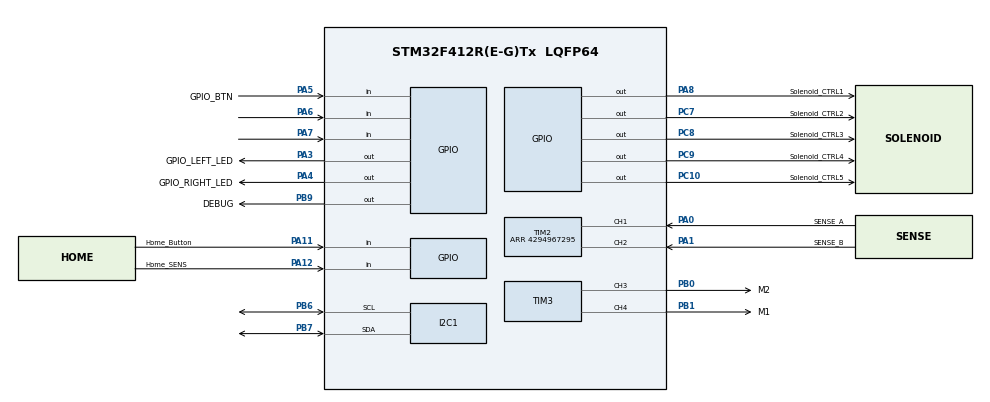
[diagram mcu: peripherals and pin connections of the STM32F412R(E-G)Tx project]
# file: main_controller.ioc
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Mcu.Family=STM32F4
Mcu.Name=STM32F412R(E-G)Tx
Mcu.Package=LQFP64
Mcu.UserConstants=TIM3autoreload,TIMxfrequency/((TIM3prescaler+1)*TIM3frequency);TIM3frequency,1000;TIM3prescaler,0;TIMxfrequency,16000000;TIM6prescaler,0;TIM6frequency,1000;TIM6autoreload,TIMxfrequency/((Tim6prescaler+1)*Tim6frequency)
NVIC.FPU_IRQn=true\:0\:0\:false\:false\:true\:true\:false\:true
NVIC.PriorityGroup=NVIC_PRIORITYGROUP_4
NVIC.TIM2_IRQn=true\:0\:0\:false\:false\:true\:true\:true\:true
NVIC.TIM3_IRQn=true\:0\:0\:false\:false\:true\:true\:true\:true
NVIC.TIM6_IRQn=true\:0\:0\:false\:false\:true\:true\:true\:true
NVIC.TIM8_UP_TIM13_IRQn=true\:15\:0\:false\:false\:true\:false\:true\:true
NVIC.TimeBase=TIM8_UP_TIM13_IRQn
NVIC.TimeBaseIP=TIM8
PA0.GPIO_Label=SENSE_A
PA0.Signal=S_TIM2_CH1_ETR
PA1.GPIO_Label=SENSE_B
PA1.Signal=S_TIM2_CH2
PA11.GPIO_Label=Home_Button
PA11.GPIO_PuPd=GPIO_NOPULL
PA11.Signal=GPIO_Input
PA12.GPIO_Label=Home_SENS
PA12.GPIO_PuPd=GPIO_PULLUP
PA12.Signal=GPIO_Input
PA13.GPIO_Label=M_SWDIO
PA13.Mode=Trace_Asynchronous_SW
PA13.Signal=SYS_JTMS-SWDIO
PA14.GPIO_Label=M_SWCLK
PA14.Mode=Trace_Asynchronous_SW
PA14.Signal=SYS_JTCK-SWCLK
PA3.GPIO_Label=GPIO_LEFT_LED
PA3.Signal=GPIO_Output
PA4.GPIO_Label=GPIO_RIGHT_LED
PA4.Signal=GPIO_Output
PA5.GPIO_Label=GPIO_BTN
PA5.GPIO_PuPd=GPIO_PULLUP
PA5.Signal=GPIO_Input
PA6.GPIO_PuPd=GPIO_PULLUP
PA6.Signal=GPIO_Input
PA7.GPIO_PuPd=GPIO_PULLUP
PA7.Signal=GPIO_Input
PA8.GPIO_Label=Solenoid_CTRL1
PA8.Signal=GPIO_Output
PB0.GPIO_Label=M2
PB0.GPIO_PuPd=GPIO_NOPULL
PB0.Signal=S_TIM3_CH3
PB1.GPIO_Label=M1
PB1.Signal=S_TIM3_CH4
PB3.GPIO_Label=M_SWO
PB3.Mode=Trace_Asynchronous_SW
PB3.Signal=SYS_JTDO-SWO
PB6.Mode=I2C
PB6.Signal=I2C1_SCL
PB7.Mode=I2C
PB7.Signal=I2C1_SDA
PB9.GPIO_Label=DEBUG
PB9.Signal=GPIO_Output
PC10.GPIO_Label=Solenoid_CTRL5
PC10.Signal=GPIO_Output
PC7.GPIO_Label=Solenoid_CTRL2
PC7.Signal=GPIO_Output
PC8.GPIO_Label=Solenoid_CTRL3
PC8.Signal=GPIO_Output
PC9.GPIO_Label=Solenoid_CTRL4
PC9.Signal=GPIO_Output
PH0\ -\ OSC_IN.Mode=HSE-External-Oscillator
PH0\ -\ OSC_IN.Signal=RCC_OSC_IN
PH1\ -\ OSC_OUT.Mode=HSE-External-Oscillator
PH1\ -\ OSC_OUT.Signal=RCC_OSC_OUT
ProjectManager.HeapSize=0x200
ProjectManager.StackSize=0x400
ProjectManager.TargetToolchain=CMake
RCC.CortexFreq_Value=16000000
RCC.HSE_VALUE=8000000
RCC.PLLSourceVirtual=RCC_PLLSOURCE_HSE
RCC.USBFreq_Value=48000000
RCC.VCOOutputFreq_Value=96000000
SH.S_TIM2_CH1_ETR.0=TIM2_CH1,Encoder_Interface
SH.S_TIM2_CH2.0=TIM2_CH2,Encoder_Interface
SH.S_TIM3_CH3.0=TIM3_CH3,PWM Generation3 CH3
SH.S_TIM3_CH4.0=TIM3_CH4,PWM Generation4 CH4
TIM2.AutoReloadPreload=TIM_AUTORELOAD_PRELOAD_DISABLE
TIM2.EncoderMode=TIM_ENCODERMODE_TI12
TIM2.IC1Filter=5
TIM2.IC2Filter=0
TIM2.Period=4294967295
TIM3.AutoReloadPreload=TIM_AUTORELOAD_PRELOAD_ENABLE
TIM3.Channel-PWM\ Generation3\ CH3=TIM_CHANNEL_3
TIM3.Channel-PWM\ Generation4\ CH4=TIM_CHANNEL_4
TIM3.Period=TIM3autoreload
TIM3.Prescaler=TIM3prescaler
TIM6.AutoReloadPreload=TIM_AUTORELOAD_PRELOAD_ENABLE
TIM6.Period=16000
TIM6.Prescaler=0
TIM6.TIM_MasterOutputTrigger=TIM_TRGO_UPDATE
VP_SYS_VS_tim8.Mode=TIM8
VP_TIM6_VS_ClockSourceINT.Mode=Enable_Timer
board=custom

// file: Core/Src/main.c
/* USER CODE BEGIN Header */
/**
  ******************************************************************************
  * @file           : main.c
  * @brief          : Main program body
  ******************************************************************************
  * @attention
  *
  * Copyright (c) 2026 STMicroelectronics.
  * All rights reserved.
  *
  * This software is licensed under terms that can be found in the LICENSE file
  * in the root directory of this software component.
  * If no LICENSE file comes with this software, it is provided AS-IS.
  *
  ******************************************************************************
  */
/* USER CODE END Header */
#include "main.h"

/* USER CODE BEGIN Includes */
#include "stm32f412rx.h"
#include "stm32f4xx_hal.h"

#include "app_main.h"

#include "SEGGER_RTT.h"
#include "SEGGER_RTT_Conf.h"
#include "stm32f4xx_hal.h"
#include "stm32f4xx_hal_tim.h"
#include <stdint.h>

/* USER CODE END Includes */

I2C_HandleTypeDef hi2c1;

TIM_HandleTypeDef htim2;
TIM_HandleTypeDef htim3;
TIM_HandleTypeDef htim6;

void SystemClock_Config(void);
static void MX_GPIO_Init(void);
static void MX_I2C1_Init(void);
static void MX_TIM3_Init(void);
static void MX_TIM2_Init(void);
static void MX_TIM6_Init(void);

int main(void)
{

  /* MCU Configuration--------------------------------------------------------*/

  /* Reset of all peripherals, Initializes the Flash interface and the Systick. */
  HAL_Init();

  /* Configure the system clock */
  SystemClock_Config();

  /* Initialize all configured peripherals */
  MX_GPIO_Init();
  MX_I2C1_Init();
  MX_TIM3_Init();
  MX_TIM2_Init();
  MX_TIM6_Init();
  /* USER CODE BEGIN 2 */
  HAL_TIM_Base_Start_IT(&htim6);

  App_Init();

  /* USER CODE END 2 */

  /* Infinite loop */
  while (1)
  {

    /* USER CODE BEGIN 3 */
    App_Tick();

  }
  /* USER CODE END 3 */
}

void SystemClock_Config(void)
{
  RCC_OscInitTypeDef RCC_OscInitStruct = {0};
  RCC_ClkInitTypeDef RCC_ClkInitStruct = {0};

  /** Configure the main internal regulator output voltage
  */
  __HAL_RCC_PWR_CLK_ENABLE();
  __HAL_PWR_VOLTAGESCALING_CONFIG(PWR_REGULATOR_VOLTAGE_SCALE1);

  /** Initializes the RCC Oscillators according to the specified parameters
  * in the RCC_OscInitTypeDef structure.
  */
  RCC_OscInitStruct.OscillatorType = RCC_OSCILLATORTYPE_HSI;
  RCC_OscInitStruct.HSIState = RCC_HSI_ON;
  RCC_OscInitStruct.HSICalibrationValue = RCC_HSICALIBRATION_DEFAULT;
  RCC_OscInitStruct.PLL.PLLState = RCC_PLL_NONE;
  if (HAL_RCC_OscConfig(&RCC_OscInitStruct) != HAL_OK)
  {
    Error_Handler();
  }

  /** Initializes the CPU, AHB and APB buses clocks
  */
  RCC_ClkInitStruct.ClockType = RCC_CLOCKTYPE_HCLK|RCC_CLOCKTYPE_SYSCLK
                              |RCC_CLOCKTYPE_PCLK1|RCC_CLOCKTYPE_PCLK2;
  RCC_ClkInitStruct.SYSCLKSource = RCC_SYSCLKSOURCE_HSI;
  RCC_ClkInitStruct.AHBCLKDivider = RCC_SYSCLK_DIV1;
  RCC_ClkInitStruct.APB1CLKDivider = RCC_HCLK_DIV1;
  RCC_ClkInitStruct.APB2CLKDivider = RCC_HCLK_DIV1;

  if (HAL_RCC_ClockConfig(&RCC_ClkInitStruct, FLASH_LATENCY_0) != HAL_OK)
  {
    Error_Handler();
  }
}

static void MX_I2C1_Init(void)
{

  hi2c1.Instance = I2C1;
  hi2c1.Init.ClockSpeed = 100000;
  hi2c1.Init.DutyCycle = I2C_DUTYCYCLE_2;
  hi2c1.Init.OwnAddress1 = 0;
  hi2c1.Init.AddressingMode = I2C_ADDRESSINGMODE_7BIT;
  hi2c1.Init.DualAddressMode = I2C_DUALADDRESS_DISABLE;
  hi2c1.Init.OwnAddress2 = 0;
  hi2c1.Init.GeneralCallMode = I2C_GENERALCALL_DISABLE;
  hi2c1.Init.NoStretchMode = I2C_NOSTRETCH_DISABLE;
  if (HAL_I2C_Init(&hi2c1) != HAL_OK)
  {
    Error_Handler();
  }

}

static void MX_TIM2_Init(void)
{

  TIM_Encoder_InitTypeDef sConfig = {0};
  TIM_MasterConfigTypeDef sMasterConfig = {0};

  htim2.Instance = TIM2;
  htim2.Init.Prescaler = 0;
  htim2.Init.CounterMode = TIM_COUNTERMODE_UP;
  htim2.Init.Period = 4294967295;
  htim2.Init.ClockDivision = TIM_CLOCKDIVISION_DIV1;
  htim2.Init.AutoReloadPreload = TIM_AUTORELOAD_PRELOAD_DISABLE;
  sConfig.EncoderMode = TIM_ENCODERMODE_TI12;
  sConfig.IC1Polarity = TIM_ICPOLARITY_RISING;
  sConfig.IC1Selection = TIM_ICSELECTION_DIRECTTI;
  sConfig.IC1Prescaler = TIM_ICPSC_DIV1;
  sConfig.IC1Filter = 5;
  sConfig.IC2Polarity = TIM_ICPOLARITY_RISING;
  sConfig.IC2Selection = TIM_ICSELECTION_DIRECTTI;
  sConfig.IC2Prescaler = TIM_ICPSC_DIV1;
  sConfig.IC2Filter = 0;
  if (HAL_TIM_Encoder_Init(&htim2, &sConfig) != HAL_OK)
  {
    Error_Handler();
  }
  sMasterConfig.MasterOutputTrigger = TIM_TRGO_RESET;
  sMasterConfig.MasterSlaveMode = TIM_MASTERSLAVEMODE_DISABLE;
  if (HAL_TIMEx_MasterConfigSynchronization(&htim2, &sMasterConfig) != HAL_OK)
  {
    Error_Handler();
  }

}

static void MX_TIM3_Init(void)
{

  TIM_MasterConfigTypeDef sMasterConfig = {0};
  TIM_OC_InitTypeDef sConfigOC = {0};

  htim3.Instance = TIM3;
  htim3.Init.Prescaler = TIM3prescaler;
  htim3.Init.CounterMode = TIM_COUNTERMODE_UP;
  htim3.Init.Period = TIM3autoreload;
  htim3.Init.ClockDivision = TIM_CLOCKDIVISION_DIV1;
  htim3.Init.AutoReloadPreload = TIM_AUTORELOAD_PRELOAD_ENABLE;
  if (HAL_TIM_PWM_Init(&htim3) != HAL_OK)
  {
    Error_Handler();
  }
  sMasterConfig.MasterOutputTrigger = TIM_TRGO_RESET;
  sMasterConfig.MasterSlaveMode = TIM_MASTERSLAVEMODE_DISABLE;
  if (HAL_TIMEx_MasterConfigSynchronization(&htim3, &sMasterConfig) != HAL_OK)
  {
    Error_Handler();
  }
  sConfigOC.OCMode = TIM_OCMODE_PWM1;
  sConfigOC.Pulse = 0;
  sConfigOC.OCPolarity = TIM_OCPOLARITY_HIGH;
  sConfigOC.OCFastMode = TIM_OCFAST_DISABLE;
  if (HAL_TIM_PWM_ConfigChannel(&htim3, &sConfigOC, TIM_CHANNEL_3) != HAL_OK)
  {
    Error_Handler();
  }
  if (HAL_TIM_PWM_ConfigChannel(&htim3, &sConfigOC, TIM_CHANNEL_4) != HAL_OK)
  {
    Error_Handler();
  }
  HAL_TIM_MspPostInit(&htim3);

}

static void MX_TIM6_Init(void)
{

  TIM_MasterConfigTypeDef sMasterConfig = {0};

  htim6.Instance = TIM6;
  htim6.Init.Prescaler = 0;
  htim6.Init.CounterMode = TIM_COUNTERMODE_UP;
  htim6.Init.Period = 16000;
  htim6.Init.AutoReloadPreload = TIM_AUTORELOAD_PRELOAD_ENABLE;
  if (HAL_TIM_Base_Init(&htim6) != HAL_OK)
  {
    Error_Handler();
  }
  sMasterConfig.MasterOutputTrigger = TIM_TRGO_UPDATE;
  sMasterConfig.MasterSlaveMode = TIM_MASTERSLAVEMODE_DISABLE;
  if (HAL_TIMEx_MasterConfigSynchronization(&htim6, &sMasterConfig) != HAL_OK)
  {
    Error_Handler();
  }

}

static void MX_GPIO_Init(void)
{
  GPIO_InitTypeDef GPIO_InitStruct = {0};

  /* GPIO Ports Clock Enable */
  __HAL_RCC_GPIOH_CLK_ENABLE();
  __HAL_RCC_GPIOA_CLK_ENABLE();
  __HAL_RCC_GPIOB_CLK_ENABLE();
  __HAL_RCC_GPIOC_CLK_ENABLE();

  /*Configure GPIO pin Output Level */
  HAL_GPIO_WritePin(GPIOA, GPIO_LEFT_LED_Pin|GPIO_RIGHT_LED_Pin|Solenoid_CTRL1_Pin, GPIO_PIN_RESET);

  /*Configure GPIO pin Output Level */
  HAL_GPIO_WritePin(GPIOC, Solenoid_CTRL2_Pin|Solenoid_CTRL3_Pin|Solenoid_CTRL4_Pin|Solenoid_CTRL5_Pin, GPIO_PIN_RESET);

  /*Configure GPIO pin Output Level */
  HAL_GPIO_WritePin(DEBUG_GPIO_Port, DEBUG_Pin, GPIO_PIN_RESET);

  /*Configure GPIO pins : GPIO_LEFT_LED_Pin GPIO_RIGHT_LED_Pin Solenoid_CTRL1_Pin */
  GPIO_InitStruct.Pin = GPIO_LEFT_LED_Pin|GPIO_RIGHT_LED_Pin|Solenoid_CTRL1_Pin;
  GPIO_InitStruct.Mode = GPIO_MODE_OUTPUT_PP;
  GPIO_InitStruct.Pull = GPIO_NOPULL;
  GPIO_InitStruct.Speed = GPIO_SPEED_FREQ_LOW;
  HAL_GPIO_Init(GPIOA, &GPIO_InitStruct);

  /*Configure GPIO pins : GPIO_BTN_Pin PA6 PA7 Home_SENS_Pin */
  GPIO_InitStruct.Pin = GPIO_BTN_Pin|GPIO_PIN_6|GPIO_PIN_7|Home_SENS_Pin;
  GPIO_InitStruct.Mode = GPIO_MODE_INPUT;
  GPIO_InitStruct.Pull = GPIO_PULLUP;
  HAL_GPIO_Init(GPIOA, &GPIO_InitStruct);

  /*Configure GPIO pins : Solenoid_CTRL2_Pin Solenoid_CTRL3_Pin Solenoid_CTRL4_Pin Solenoid_CTRL5_Pin */
  GPIO_InitStruct.Pin = Solenoid_CTRL2_Pin|Solenoid_CTRL3_Pin|Solenoid_CTRL4_Pin|Solenoid_CTRL5_Pin;
  GPIO_InitStruct.Mode = GPIO_MODE_OUTPUT_PP;
  GPIO_InitStruct.Pull = GPIO_NOPULL;
  GPIO_InitStruct.Speed = GPIO_SPEED_FREQ_LOW;
  HAL_GPIO_Init(GPIOC, &GPIO_InitStruct);

  /*Configure GPIO pin : Home_Button_Pin */
  GPIO_InitStruct.Pin = Home_Button_Pin;
  GPIO_InitStruct.Mode = GPIO_MODE_INPUT;
  GPIO_InitStruct.Pull = GPIO_NOPULL;
  HAL_GPIO_Init(Home_Button_GPIO_Port, &GPIO_InitStruct);

  /*Configure GPIO pin : DEBUG_Pin */
  GPIO_InitStruct.Pin = DEBUG_Pin;
  GPIO_InitStruct.Mode = GPIO_MODE_OUTPUT_PP;
  GPIO_InitStruct.Pull = GPIO_NOPULL;
  GPIO_InitStruct.Speed = GPIO_SPEED_FREQ_LOW;
  HAL_GPIO_Init(DEBUG_GPIO_Port, &GPIO_InitStruct);

}

void HAL_TIM_PeriodElapsedCallback(TIM_HandleTypeDef *htim)
{
  if (htim->Instance == TIM8)
  {
    HAL_IncTick();
  }
  /* USER CODE BEGIN Callback 1 */
  if (htim->Instance == TIM6)
  {
    App_SetControlFlag();
  }
  /* USER CODE END Callback 1 */
}

void Error_Handler(void)
{
  __disable_irq();
  while (1)
  {
  }
}
